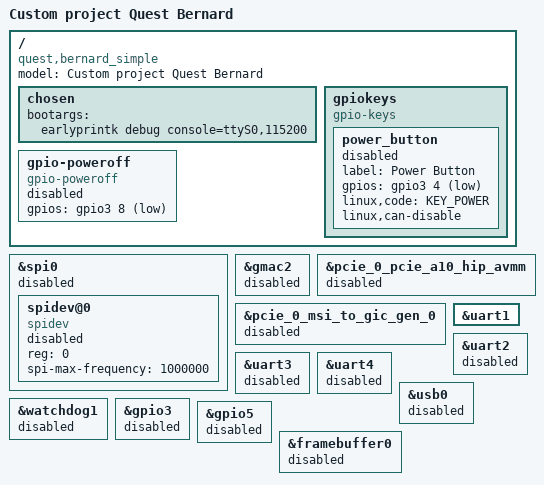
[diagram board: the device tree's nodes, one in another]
/*
 *  Copyright (C) 2018 Quest Innovations <www.quest-innovations.com>
 *
 * This program is free software; you can redistribute it and/or modify
 * it under the terms of the GNU General Public License as published by
 * the Free Software Foundation; either version 2 of the License, or
 * (at your option) any later version.
 *
 * This program is distributed in the hope that it will be useful,
 * but WITHOUT ANY WARRANTY; without even the implied warranty of
 * MERCHANTABILITY or FITNESS FOR A PARTICULAR PURPOSE.  See the
 * GNU General Public License for more details.
 *
 * You should have received a copy of the GNU General Public License
 * along with this program.  If not, see <http://www.gnu.org/licenses/>.
 */

/dts-v1/;
#include "socfpga_arria10_bernard_base.dtsi"
#include <dt-bindings/interrupt-controller/irq.h>
#include <dt-bindings/gpio/gpio.h>
#include <dt-bindings/input/input.h>

/ {
	model = "Custom project Quest Bernard";
	compatible = "quest,bernard_simple", "altr,socfpga-arria10", "altr,socfpga";

	chosen {
		bootargs = "earlyprintk debug console=ttyS0,115200";
	};

	gpiokeys {
		compatible = "gpio-keys";
		power_button {
			label = "Power Button";
			gpios = <&gpio3 4 GPIO_ACTIVE_LOW>;
			//linux,code = <KEY_A>;
			linux,code = <KEY_POWER>;
			linux,can-disable;
			status = "disabled";
		};
		
	};
	gpio-poweroff {
		compatible = "gpio-poweroff";
		gpios = <&gpio3 8 GPIO_ACTIVE_LOW>;
			status = "disabled";
	};
};

&spi0 {

	status = "disabled";
	spidev@0 {
		compatible = "spidev";
		reg = <0>;
		spi-max-frequency = <1000000>;
		status = "disabled";
	};
};

&gmac2 {
	status = "disabled";
};

&pcie_0_pcie_a10_hip_avmm {
	status = "disabled";	
};

&pcie_0_msi_to_gic_gen_0 {
	status = "disabled";	
};

&uart1 {
	status = "okay";
};

&uart2 {
	status = "disabled";
};

&uart3 {
	status = "disabled";
};

&uart4 {
	status = "disabled";
};

&usb0 {
	status = "disabled";
};

&watchdog1 {
	status = "disabled";
};

&gpio3 {
	status = "disabled";
};

&gpio5 {
	status = "disabled";
};

&framebuffer0 {
	status = "disabled";
};
